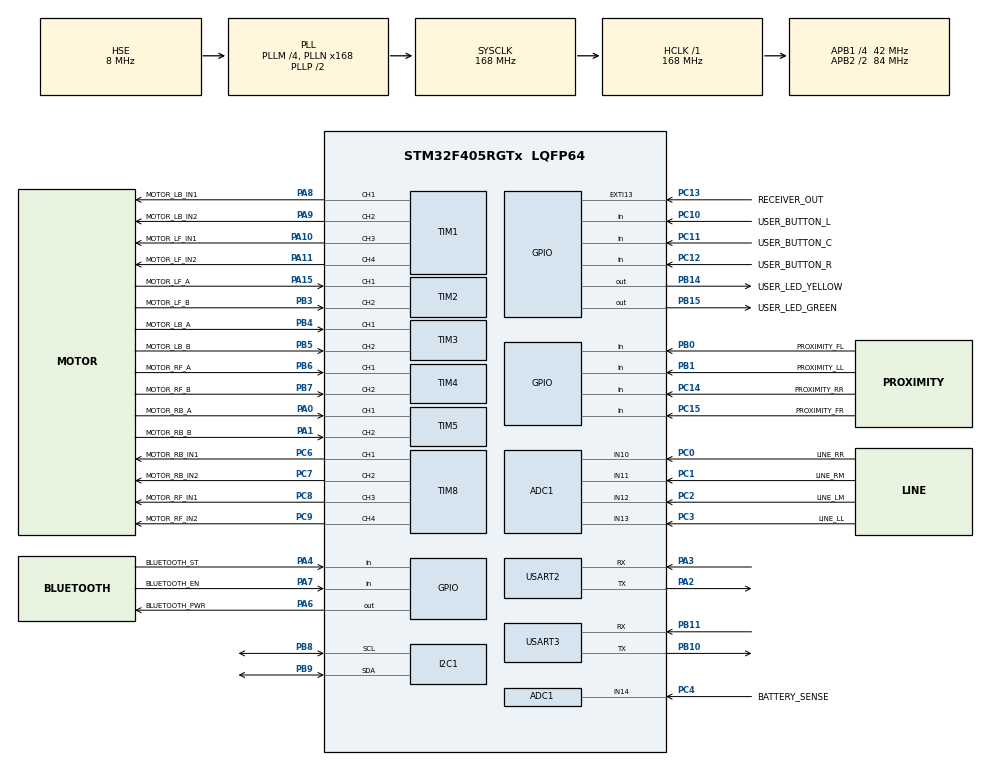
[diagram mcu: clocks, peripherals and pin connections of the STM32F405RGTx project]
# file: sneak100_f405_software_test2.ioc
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ADC1.Channel-1\#ChannelRegularConversion=ADC_CHANNEL_10
ADC1.NbrOfConversionFlag=1
ADC1.Rank-1\#ChannelRegularConversion=1
ADC1.SamplingTime-1\#ChannelRegularConversion=ADC_SAMPLETIME_3CYCLES
ADC1.master=1
Mcu.Family=STM32F4
Mcu.Name=STM32F405RGTx
Mcu.Package=LQFP64
NVIC.PriorityGroup=NVIC_PRIORITYGROUP_4
NVIC.TIM6_DAC_IRQn=true\:0\:0\:false\:false\:true\:false\:true
NVIC.TimeBase=TIM6_DAC_IRQn
NVIC.TimeBaseIP=TIM6
PA0-WKUP.GPIO_Label=MOTOR_RB_A
PA0-WKUP.Signal=S_TIM5_CH1
PA1.GPIO_Label=MOTOR_RB_B
PA1.Signal=S_TIM5_CH2
PA10.GPIO_Label=MOTOR_LF_IN1
PA10.Signal=S_TIM1_CH3
PA11.GPIO_Label=MOTOR_LF_IN2
PA11.Signal=S_TIM1_CH4
PA13.Mode=Serial_Wire
PA13.Signal=SYS_JTMS-SWDIO
PA14.Mode=Serial_Wire
PA14.Signal=SYS_JTCK-SWCLK
PA15.GPIO_Label=MOTOR_LF_A
PA15.Signal=S_TIM2_CH1_ETR
PA2.Mode=Asynchronous
PA2.Signal=USART2_TX
PA3.Mode=Asynchronous
PA3.Signal=USART2_RX
PA4.GPIO_Label=BLUETOOTH_ST
PA4.Signal=GPIO_Input
PA6.GPIO_Label=BLUETOOTH_PWR
PA6.GPIO_ModeDefaultOutputPP=GPIO_MODE_OUTPUT_OD
PA6.Signal=GPIO_Output
PA7.GPIO_Label=BLUETOOTH_EN
PA7.Signal=GPIO_Input
PA8.GPIO_Label=MOTOR_LB_IN1
PA8.Signal=S_TIM1_CH1
PA9.GPIO_Label=MOTOR_LB_IN2
PA9.Signal=S_TIM1_CH2
PB0.GPIO_Label=PROXIMITY_FL
PB0.Signal=GPIO_Input
PB1.GPIO_Label=PROXIMITY_LL
PB1.Signal=GPIO_Input
PB10.Mode=Asynchronous
PB10.Signal=USART3_TX
PB11.Mode=Asynchronous
PB11.Signal=USART3_RX
PB14.GPIO_Label=USER_LED_YELLOW
PB14.Signal=GPIO_Output
PB15.GPIO_Label=USER_LED_GREEN
PB15.Signal=GPIO_Output
PB3.GPIO_Label=MOTOR_LF_B
PB3.Signal=S_TIM2_CH2
PB4.GPIO_Label=MOTOR_LB_A
PB4.Signal=S_TIM3_CH1
PB5.GPIO_Label=MOTOR_LB_B
PB5.Signal=S_TIM3_CH2
PB6.GPIO_Label=MOTOR_RF_A
PB6.Signal=S_TIM4_CH1
PB7.GPIO_Label=MOTOR_RF_B
PB7.Signal=S_TIM4_CH2
PB8.Mode=I2C
PB8.Signal=I2C1_SCL
PB9.Mode=I2C
PB9.Signal=I2C1_SDA
PC0.GPIO_Label=LINE_RR
PC0.Signal=ADCx_IN10
PC1.GPIO_Label=LINE_RM
PC1.Signal=ADCx_IN11
PC10.GPIO_Label=USER_BUTTON_L
PC10.Signal=GPIO_Input
PC11.GPIO_Label=USER_BUTTON_C
PC11.Signal=GPIO_Input
PC12.GPIO_Label=USER_BUTTON_R
PC12.Signal=GPIO_Input
PC13-ANTI_TAMP.GPIO_Label=RECEIVER_OUT
PC13-ANTI_TAMP.Signal=GPXTI13
PC14-OSC32_IN.GPIO_Label=PROXIMITY_RR
PC14-OSC32_IN.Signal=GPIO_Input
PC15-OSC32_OUT.GPIO_Label=PROXIMITY_FR
PC15-OSC32_OUT.Signal=GPIO_Input
PC2.GPIO_Label=LINE_LM
PC2.Signal=ADCx_IN12
PC3.GPIO_Label=LINE_LL
PC3.Signal=ADCx_IN13
PC4.GPIO_Label=BATTERY_SENSE
PC4.Signal=ADCx_IN14
PC6.GPIO_Label=MOTOR_RB_IN1
PC6.Signal=S_TIM8_CH1
PC7.GPIO_Label=MOTOR_RB_IN2
PC7.Signal=S_TIM8_CH2
PC8.GPIO_Label=MOTOR_RF_IN1
PC8.Signal=S_TIM8_CH3
PC9.GPIO_Label=MOTOR_RF_IN2
PC9.Signal=S_TIM8_CH4
PH0-OSC_IN.Mode=HSE-External-Oscillator
PH0-OSC_IN.Signal=RCC_OSC_IN
PH1-OSC_OUT.Mode=HSE-External-Oscillator
PH1-OSC_OUT.Signal=RCC_OSC_OUT
ProjectManager.HeapSize=0x200
ProjectManager.StackSize=0x400
ProjectManager.TargetToolchain=STM32CubeIDE
RCC.48MHZClocksFreq_Value=84000000
RCC.AHBFreq_Value=168000000
RCC.APB1CLKDivider=RCC_HCLK_DIV4
RCC.APB1Freq_Value=42000000
RCC.APB1TimFreq_Value=84000000
RCC.APB2CLKDivider=RCC_HCLK_DIV2
RCC.APB2Freq_Value=84000000
RCC.APB2TimFreq_Value=168000000
RCC.CortexFreq_Value=168000000
RCC.HCLKFreq_Value=168000000
RCC.HSE_VALUE=8000000
RCC.HSI_VALUE=16000000
RCC.LSE_VALUE=32768
RCC.PLLM=4
RCC.PLLN=168
RCC.PLLSourceVirtual=RCC_PLLSOURCE_HSE
RCC.SYSCLKFreq_VALUE=168000000
RCC.SYSCLKSource=RCC_SYSCLKSOURCE_PLLCLK
RCC.VCOOutputFreq_Value=336000000
SH.ADCx_IN10.0=ADC1_IN10,IN10
SH.ADCx_IN11.0=ADC1_IN11,IN11
SH.ADCx_IN12.0=ADC1_IN12,IN12
SH.ADCx_IN13.0=ADC1_IN13,IN13
SH.ADCx_IN14.0=ADC1_IN14,IN14
SH.S_TIM1_CH1.0=TIM1_CH1,PWM Generation1 CH1
SH.S_TIM1_CH2.0=TIM1_CH2,PWM Generation2 CH2
SH.S_TIM1_CH3.0=TIM1_CH3,PWM Generation3 CH3
SH.S_TIM1_CH4.0=TIM1_CH4,PWM Generation4 CH4
SH.S_TIM2_CH1_ETR.0=TIM2_CH1,Encoder_Interface
SH.S_TIM2_CH2.0=TIM2_CH2,Encoder_Interface
SH.S_TIM3_CH1.0=TIM3_CH1,Encoder_Interface
SH.S_TIM3_CH2.0=TIM3_CH2,Encoder_Interface
SH.S_TIM4_CH1.0=TIM4_CH1,Encoder_Interface
SH.S_TIM4_CH2.0=TIM4_CH2,Encoder_Interface
SH.S_TIM5_CH1.0=TIM5_CH1,Encoder_Interface
SH.S_TIM5_CH2.0=TIM5_CH2,Encoder_Interface
SH.S_TIM8_CH1.0=TIM8_CH1,PWM Generation1 CH1
SH.S_TIM8_CH2.0=TIM8_CH2,PWM Generation2 CH2
SH.S_TIM8_CH3.0=TIM8_CH3,PWM Generation3 CH3
SH.S_TIM8_CH4.0=TIM8_CH4,PWM Generation4 CH4
TIM1.Channel-PWM\ Generation1\ CH1=TIM_CHANNEL_1
TIM1.Channel-PWM\ Generation2\ CH2=TIM_CHANNEL_2
TIM1.Channel-PWM\ Generation3\ CH3=TIM_CHANNEL_3
TIM1.Channel-PWM\ Generation4\ CH4=TIM_CHANNEL_4
TIM8.Channel-PWM\ Generation1\ CH1=TIM_CHANNEL_1
TIM8.Channel-PWM\ Generation2\ CH2=TIM_CHANNEL_2
TIM8.Channel-PWM\ Generation3\ CH3=TIM_CHANNEL_3
TIM8.Channel-PWM\ Generation4\ CH4=TIM_CHANNEL_4
USART2.VirtualMode=VM_ASYNC
USART3.VirtualMode=VM_ASYNC
VP_ADC1_TempSens_Input.Mode=IN-TempSens
VP_SYS_VS_tim6.Mode=TIM6
board=custom

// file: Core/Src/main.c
/* USER CODE BEGIN Header */
/**
  ******************************************************************************
  * @file           : main.c
  * @brief          : Main program body
  ******************************************************************************
  * @attention
  *
  * <h2><center>&copy; Copyright (c) 2021 STMicroelectronics.
  * All rights reserved.</center></h2>
  *
  * This software component is licensed by ST under BSD 3-Clause license,
  * the "License"; You may not use this file except in compliance with the
  * License. You may obtain a copy of the License at:
  *                        opensource.org/licenses/BSD-3-Clause
  *
  ******************************************************************************
  */
/* USER CODE END Header */
#include "main.h"
#include "adc.h"
#include "i2c.h"
#include "tim.h"
#include "usart.h"
#include "gpio.h"

void SystemClock_Config(void);

int main(void)
{

  /* MCU Configuration--------------------------------------------------------*/

  /* Reset of all peripherals, Initializes the Flash interface and the Systick. */
  HAL_Init();

  /* Configure the system clock */
  SystemClock_Config();

  /* Initialize all configured peripherals */
  MX_GPIO_Init();
  MX_I2C1_Init();
  MX_TIM2_Init();
  MX_TIM3_Init();
  MX_TIM4_Init();
  MX_TIM8_Init();
  MX_USART2_UART_Init();
  MX_TIM1_Init();
  MX_USART3_UART_Init();
  MX_TIM5_Init();
  MX_ADC1_Init();

  /* Infinite loop */
  /* USER CODE BEGIN WHILE */
  while (1)
  {
	  HAL_GPIO_TogglePin(USER_LED_GREEN_GPIO_Port, USER_LED_GREEN_Pin);
	  HAL_Delay(250);
	  HAL_GPIO_TogglePin(USER_LED_YELLOW_GPIO_Port, USER_LED_YELLOW_Pin);
	  HAL_Delay(250);

    /* USER CODE END WHILE */

  }
}

void SystemClock_Config(void)
{
  RCC_OscInitTypeDef RCC_OscInitStruct = {0};
  RCC_ClkInitTypeDef RCC_ClkInitStruct = {0};

  /** Configure the main internal regulator output voltage
  */
  __HAL_RCC_PWR_CLK_ENABLE();
  __HAL_PWR_VOLTAGESCALING_CONFIG(PWR_REGULATOR_VOLTAGE_SCALE1);
  /** Initializes the RCC Oscillators according to the specified parameters
  * in the RCC_OscInitTypeDef structure.
  */
  RCC_OscInitStruct.OscillatorType = RCC_OSCILLATORTYPE_HSE;
  RCC_OscInitStruct.HSEState = RCC_HSE_ON;
  RCC_OscInitStruct.PLL.PLLState = RCC_PLL_ON;
  RCC_OscInitStruct.PLL.PLLSource = RCC_PLLSOURCE_HSE;
  RCC_OscInitStruct.PLL.PLLM = 4;
  RCC_OscInitStruct.PLL.PLLN = 168;
  RCC_OscInitStruct.PLL.PLLP = RCC_PLLP_DIV2;
  RCC_OscInitStruct.PLL.PLLQ = 4;
  if (HAL_RCC_OscConfig(&RCC_OscInitStruct) != HAL_OK)
  {
    Error_Handler();
  }
  /** Initializes the CPU, AHB and APB buses clocks
  */
  RCC_ClkInitStruct.ClockType = RCC_CLOCKTYPE_HCLK|RCC_CLOCKTYPE_SYSCLK
                              |RCC_CLOCKTYPE_PCLK1|RCC_CLOCKTYPE_PCLK2;
  RCC_ClkInitStruct.SYSCLKSource = RCC_SYSCLKSOURCE_PLLCLK;
  RCC_ClkInitStruct.AHBCLKDivider = RCC_SYSCLK_DIV1;
  RCC_ClkInitStruct.APB1CLKDivider = RCC_HCLK_DIV4;
  RCC_ClkInitStruct.APB2CLKDivider = RCC_HCLK_DIV2;

  if (HAL_RCC_ClockConfig(&RCC_ClkInitStruct, FLASH_LATENCY_5) != HAL_OK)
  {
    Error_Handler();
  }
}

 /**
  * @brief  Period elapsed callback in non blocking mode
  * @note   This function is called  when TIM6 interrupt took place, inside
  * HAL_TIM_IRQHandler(). It makes a direct call to HAL_IncTick() to increment
  * a global variable "uwTick" used as application time base.
  * @param  htim : TIM handle
  * @retval None
  */
void HAL_TIM_PeriodElapsedCallback(TIM_HandleTypeDef *htim)
{
  if (htim->Instance == TIM6) {
    HAL_IncTick();
  }
}

void Error_Handler(void)
{
  __disable_irq();
  while (1)
  {
  }
}

/************************ (C) COPYRIGHT STMicroelectronics *****END OF FILE****/
